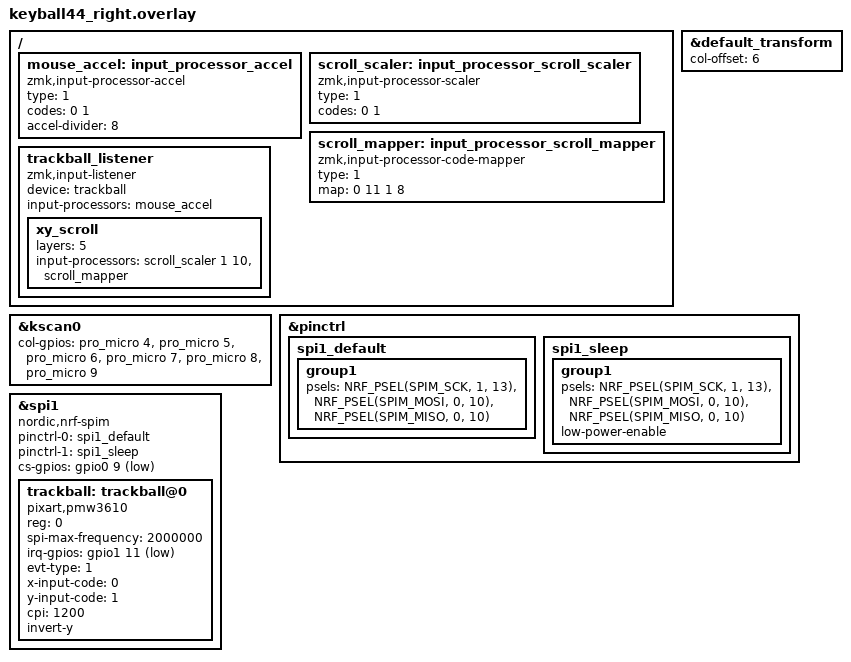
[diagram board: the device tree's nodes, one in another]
/*
 * Copyright (c) 2020 ZMK Contributors
 *
 * SPDX-License-Identifier: MIT
 */
 
#include "keyball44.dtsi"

&default_transform {
    col-offset = <6>;
};

&kscan0 {
	col-gpios
		= <&pro_micro 4 GPIO_ACTIVE_HIGH>
		, <&pro_micro 5 GPIO_ACTIVE_HIGH>
		, <&pro_micro 6 GPIO_ACTIVE_HIGH>
		, <&pro_micro 7 GPIO_ACTIVE_HIGH>
		, <&pro_micro 8 GPIO_ACTIVE_HIGH>
        , <&pro_micro 9 GPIO_ACTIVE_HIGH>
		;
};

&pinctrl {
    spi1_default: spi1_default {
        group1 {
            psels = <NRF_PSEL(SPIM_SCK, 1, 13)>,
                <NRF_PSEL(SPIM_MOSI, 0, 10)>,
                <NRF_PSEL(SPIM_MISO, 0, 10)>;
        };
    };

    spi1_sleep: spi1_sleep {
        group1 {
            psels = <NRF_PSEL(SPIM_SCK, 1, 13)>,
                <NRF_PSEL(SPIM_MOSI, 0, 10)>,
                <NRF_PSEL(SPIM_MISO, 0, 10)>;
            low-power-enable;
        };
    };
};

&spi1 {
    status = "okay";
    compatible = "nordic,nrf-spim";
    pinctrl-0 = <&spi1_default>;
    pinctrl-1 = <&spi1_sleep>;
    pinctrl-names = "default", "sleep";
    cs-gpios = <&gpio0 9 GPIO_ACTIVE_LOW>;

    trackball: trackball@0 {
        status = "okay";
        compatible = "pixart,pmw3610";
        reg = <0>;
        spi-max-frequency = <2000000>;
        irq-gpios = <&gpio1 11 (GPIO_ACTIVE_LOW | GPIO_PULL_UP)>;
        evt-type = <1>;  // INPUT_EV_REL
        x-input-code = <0>;  // INPUT_REL_X
        y-input-code = <1>;  // INPUT_REL_Y
        cpi = <1200>;
        invert-y;
    };
};

/ {
  /* Mouse acceleration input processor */
  mouse_accel: input_processor_accel {
    compatible = "zmk,input-processor-accel";
    #input-processor-cells = <0>;
    type = <1>;  // INPUT_EV_REL
    codes = <0 1>;  // INPUT_REL_X, INPUT_REL_Y
    accel-divider = <8>;  // Same as QMK config
  };

  /* Scaler for scroll mode - reduces sensitivity */
  scroll_scaler: input_processor_scroll_scaler {
    compatible = "zmk,input-processor-scaler";
    #input-processor-cells = <2>;
    type = <1>;  // INPUT_EV_REL
    codes = <0 1>;  // INPUT_REL_X, INPUT_REL_Y
  };

  /* Code mapper to convert X/Y to scroll wheel */
  scroll_mapper: input_processor_scroll_mapper {
    compatible = "zmk,input-processor-code-mapper";
    #input-processor-cells = <0>;
    type = <1>;  // INPUT_EV_REL
    map = <0 11   // INPUT_REL_X -> INPUT_REL_HWHEEL (horizontal scroll)
           1 8>;  // INPUT_REL_Y -> INPUT_REL_WHEEL (vertical scroll)
  };

  trackball_listener {
    compatible = "zmk,input-listener";
    device = <&trackball>;

    /* Default: mouse mode with acceleration */
    input-processors = <&mouse_accel>;

    /* Layer 5: scroll mode (like QMK NumLock scroll) */
    xy_scroll {
      layers = <5>;
      input-processors = <&scroll_scaler 1 10  // Scale down by 10x for smooth scrolling
                         &scroll_mapper>;
    };
  };
};
